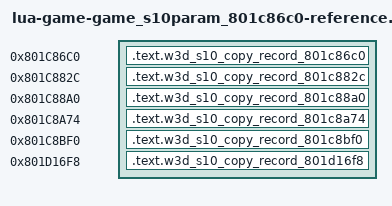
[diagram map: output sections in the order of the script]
/* Generated reference-only placements. All bodies are source-built. */
OUTPUT_FORMAT("elf32-powerpc")
OUTPUT_ARCH(powerpc)
ENTRY(w3d_s10_copy_record_801c86c0)
_SDA_BASE_ = 0x804b2540;
_SDA2_BASE_ = 0x804c2540;
SECTIONS {
  .text.w3d_s10_copy_record_801c86c0 0x801c86c0 : { *(.text.w3d_s10_copy_record_801c86c0) }
  .text.w3d_s10_copy_record_801c882c 0x801c882c : { *(.text.w3d_s10_copy_record_801c882c) }
  .text.w3d_s10_copy_record_801c88a0 0x801c88a0 : { *(.text.w3d_s10_copy_record_801c88a0) }
  .text.w3d_s10_copy_record_801c8a74 0x801c8a74 : { *(.text.w3d_s10_copy_record_801c8a74) }
  .text.w3d_s10_copy_record_801c8bf0 0x801c8bf0 : { *(.text.w3d_s10_copy_record_801c8bf0) }
  .text.w3d_s10_copy_record_801d16f8 0x801d16f8 : { *(.text.w3d_s10_copy_record_801d16f8) }
  /DISCARD/ : { *(.text*) *(.rodata*) *(.data*) *(.bss*) *(.sdata*) *(.sbss*) *(.comment) }
}
